# M3351 register map
File version: 1.0
Registers are 32-bit, read-write, reset 0x0 unless marked. A register's access mark holds for its fields unless they carry their own. Offsets are from the block's base; [hi:lo] are bit positions.

## CRC_NS — CRCNS Register Map
Base 0x5020B000
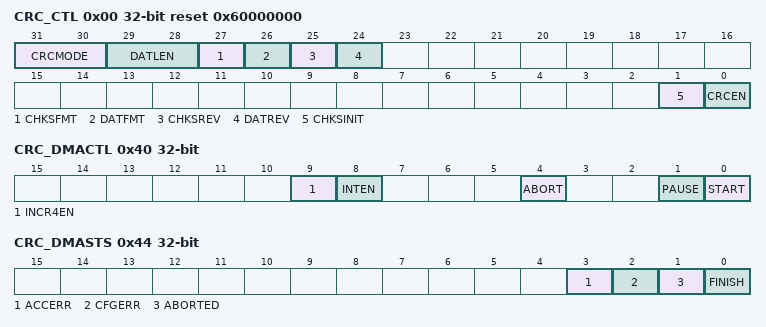
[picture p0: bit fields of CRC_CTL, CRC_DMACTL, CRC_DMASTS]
0x00 CRC_CTL reset 0x60000000 — CRC Control Register
  [31:30] CRCMODE — CRC Polynomial Mode. This field indicates the CRC operation polynomial mode.
    0=CRC-16 Polynomial mode; 1=CRC-8 Polynomial mode; 3=CRC-32 Polynomial mode
  [29:28] DATLEN — CPU Write Data Length. This field indicates the write data length. Note: When the write data length is 8-bit mode, the valid data in CRC_DAT register is only DATA[7:0] bits; if the write data length is 16-bit mode, the valid data in CRC_DAT register is only DATA[15:0].
    0=Data length is 8-bit mode; 1=Data length is 16-bit mode. Data length is 32-bit mode
  [27] CHKSFMT — Checksum 1's Complement. This bit is used to enable the 1's complement function for checksum result in CRC_CHECKSUM register.
    0=1's complement for CRC checksum Disabled; 1=1's complement for CRC checksum Enabled
  [26] DATFMT — Write Data 1's Complement. This bit is used to enable the 1's complement function for write data value in CRC_DAT register.
    0=1's complement for CRC writes data in Disabled; 1=1's complement for CRC writes data in Enabled
  [25] CHKSREV — Checksum Bit Order Reverse. This bit is used to enable the bit order reverse function for checksum result in CRC_CHECKSUM register. Note: If the checksum result is 0xDD7B0F2E, the bit order reverse for CRC checksum is 0x74F0DEBB.
    0=Bit order reverse for CRC checksum Disabled; 1=Bit order reverse for CRC checksum Enabled
  [24] DATREV — Write Data Bit Order Reverse. This bit is used to enable the bit order reverse function per byte for write data value in CRC_DAT register. Note: If the write data is 0xAABBCCDD, the bit order reverse for CRC write data in is 0x55DD33BB.
    0=Bit order reversed for CRC write data in Disabled; 1=Bit order reversed for CRC write data in Enabled (per byte)
  [1] CHKSINIT — Checksum Initialization. Note: This bit will be cleared automatically.
    0=No effect; 1=Initial checksum value by auto reload CRC_SEED register value to CRC_CHECKSUM register value
  [0] CRCEN — CRC Channel Enable Bit
    0=No effect; 1=CRC operation Enabled
0x04 CRC_DAT — CRC Write Data Register
  [31:0] DATA — CRC Write Data Bits. User can write data directly by CPU to write data to this field to perform CRC operation. Note: When the write data length is 8-bit mode, the valid data in CRC_DAT register is only DATA[7:0] bits; if the write data length is 16-bit mode, the valid data in CRC_DAT register is only DATA[15:0].
0x08 CRC_SEED reset 0xFFFFFFFF
  [31:0] SEED — CRC Seed Value. This field indicates the CRC seed value. Note: This field will be reloaded as checksum initial value (CRC_CHECKSUM register) after perform CHKSINIT (CRC_CTL[1]).
0x0C CRC_CHECKSUM ro reset 0xFFFFFFFF
  [31:0] CHECKSUM — CRC Checksum Results. This field indicates the CRC checksum result. Note: Data in CRC_CHECKSUM register has different length when user chooses different operation polynomial modes. For example: If final checksum result is 0x12 in CRC-8 polynomial mode, the CHECKSUM[31:0] value will be read as 0x12121212, only CHECKSUM[7:0] is valid in this mode. If final checksum result is 0x1234 in CRC-CCITT or CRC-16 mode, the CHECKSUM[31:0] value will be read as 0x12341234, only CHECKSUM[15:0] is valid in this mode. And the CHECKSUM[31:0] is valid for CRC-32 mode.
0x10 CRC_POLYNOMIAL
  [31:0] POLYNOMIAL — CRC Polynomial Value Results. This field indicates the value of CRC polynomial.
0x40 CRC_DMACTL — CRC DMA Mode Control Register
  [9] INCR4EN — INCR4 Enable Bit. Note: Only 4words-aligned transfer is INCR4, other transfer is single type.
    0=Single transfer type; 1=Burst INCR4 transfer enable
  [8] INTEN — CRC DMA Mode Interrupt Enable Bit. Enable CRC DMA mode interrupt.
  [4] ABORT — CRC DMA Operation Abort Bit. Write 1 to abort the operation of CRC DMA.
  [1] PAUSE — CRC DMA Pause Bit. Bit to set CRC DMA to pause the operation. When write. Note: This bit is read-as-1 when the CRC DMA is paused.
    0=Continue the CRCDMA operation when CRCDMA is under operation; 1=Pause the CRCDMA operation
  [0] START — CRC DMA Start Bit. Set CRC DMA to start operation. This bit is read-as-1 when the CRC DMA is operating. This bit can be set to 1 when all DMASTS flags are cleared to zero.
0x44 CRC_DMASTS — CRC DMA Mode Status Register
  [3] ACCERR write-1-clears — DMA Access Error Flag (Write 1 to Clear). Indicates the operation of DMA mode is aborted due to access error.
  [2] CFGERR write-1-clears — Configuration Error Flag (Write 1 to Clear). Indicates the configuration to run DMA operation is invalid and the operation of DMA mode is canceled.
  [1] ABORTED write-1-clears — DMA Operation Aborted Flag (Write 1 to Clear). Indicates the operation of DMA mode is aborted due to user setting CRC_DMACTL.ABORT bit.
  [0] FINISH write-1-clears — DMA Operation Finish Flag (Write 1 to Clear). Indicates the operation of DMA mode finished successfully.
0x48 CRC_SADDR — CRC DMA Source Address Register
  [31:2] SADDR — CRC DMA Source Address. DMA source address. This value should be less than 0xE000_0000
0x4C CRC_DMACNT — CRC DMA Word Count Register
  [27:2] DMACNT — CRC DMA Operation Word Count. Indicates words for DMA to read.
